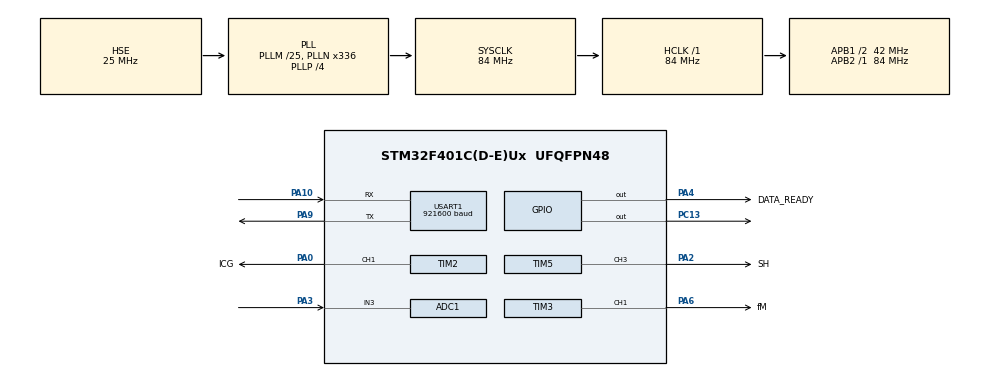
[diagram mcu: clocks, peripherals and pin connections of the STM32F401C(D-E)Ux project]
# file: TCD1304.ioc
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ADC1.Channel-0\#ChannelRegularConversion=ADC_CHANNEL_3
ADC1.ContinuousConvMode=DISABLE
ADC1.DMAContinuousRequests=ENABLE
ADC1.ExternalTrigConv=ADC_EXTERNALTRIGCONV_T4_CC4
ADC1.NbrOfConversionFlag=1
ADC1.Rank-0\#ChannelRegularConversion=1
ADC1.SamplingTime-0\#ChannelRegularConversion=ADC_SAMPLETIME_3CYCLES
ADC1.ScanConvMode=DISABLE
ADC1.master=1
Dma.ADC1.0.Direction=DMA_PERIPH_TO_MEMORY
Dma.ADC1.0.FIFOMode=DMA_FIFOMODE_DISABLE
Dma.ADC1.0.Instance=DMA2_Stream0
Dma.ADC1.0.MemDataAlignment=DMA_MDATAALIGN_HALFWORD
Dma.ADC1.0.MemInc=DMA_MINC_ENABLE
Dma.ADC1.0.Mode=DMA_CIRCULAR
Dma.ADC1.0.PeriphDataAlignment=DMA_PDATAALIGN_HALFWORD
Dma.ADC1.0.PeriphInc=DMA_PINC_DISABLE
Dma.ADC1.0.Priority=DMA_PRIORITY_LOW
Dma.Request0=ADC1
Dma.Request1=USART1_RX
Dma.Request2=USART1_TX
Dma.USART1_RX.1.Direction=DMA_PERIPH_TO_MEMORY
Dma.USART1_RX.1.FIFOMode=DMA_FIFOMODE_DISABLE
Dma.USART1_RX.1.Instance=DMA2_Stream2
Dma.USART1_RX.1.MemDataAlignment=DMA_MDATAALIGN_BYTE
Dma.USART1_RX.1.MemInc=DMA_MINC_ENABLE
Dma.USART1_RX.1.Mode=DMA_NORMAL
Dma.USART1_RX.1.PeriphDataAlignment=DMA_PDATAALIGN_BYTE
Dma.USART1_RX.1.PeriphInc=DMA_PINC_DISABLE
Dma.USART1_RX.1.Priority=DMA_PRIORITY_LOW
Dma.USART1_TX.2.Direction=DMA_MEMORY_TO_PERIPH
Dma.USART1_TX.2.FIFOMode=DMA_FIFOMODE_DISABLE
Dma.USART1_TX.2.Instance=DMA2_Stream7
Dma.USART1_TX.2.MemDataAlignment=DMA_MDATAALIGN_BYTE
Dma.USART1_TX.2.MemInc=DMA_MINC_ENABLE
Dma.USART1_TX.2.Mode=DMA_NORMAL
Dma.USART1_TX.2.PeriphDataAlignment=DMA_PDATAALIGN_BYTE
Dma.USART1_TX.2.PeriphInc=DMA_PINC_DISABLE
Dma.USART1_TX.2.Priority=DMA_PRIORITY_LOW
Mcu.Family=STM32F4
Mcu.Name=STM32F401C(D-E)Ux
Mcu.Package=UFQFPN48
NVIC.DMA2_Stream0_IRQn=true\:0\:0\:false\:false\:true\:false\:true\:true
NVIC.DMA2_Stream2_IRQn=true\:0\:0\:false\:false\:true\:false\:true\:true
NVIC.DMA2_Stream7_IRQn=true\:0\:0\:false\:false\:true\:false\:true\:true
NVIC.PriorityGroup=NVIC_PRIORITYGROUP_4
NVIC.TIM2_IRQn=true\:0\:0\:false\:false\:true\:true\:true\:true
NVIC.USART1_IRQn=true\:0\:0\:false\:false\:true\:true\:true\:true
PA0-WKUP.GPIO_Label=ICG
PA0-WKUP.Signal=S_TIM2_CH1_ETR
PA10.Mode=Asynchronous
PA10.Signal=USART1_RX
PA2.GPIO_Label=SH
PA2.Signal=S_TIM5_CH3
PA3.Signal=ADCx_IN3
PA4.GPIO_Label=DATA_READY
PA4.Signal=GPIO_Output
PA6.GPIO_Label=fM
PA6.Signal=S_TIM3_CH1
PA9.Mode=Asynchronous
PA9.Signal=USART1_TX
PC13-ANTI_TAMP.GPIO_PuPd=GPIO_PULLUP
PC13-ANTI_TAMP.PinState=GPIO_PIN_SET
PC13-ANTI_TAMP.Signal=GPIO_Output
PH0\ -\ OSC_IN.Mode=HSE-External-Oscillator
PH0\ -\ OSC_IN.Signal=RCC_OSC_IN
PH1\ -\ OSC_OUT.Mode=HSE-External-Oscillator
PH1\ -\ OSC_OUT.Signal=RCC_OSC_OUT
ProjectManager.HeapSize=0x200
ProjectManager.StackSize=0x400
ProjectManager.TargetToolchain=STM32CubeIDE
RCC.48MHZClocksFreq_Value=48000000
RCC.AHBFreq_Value=84000000
RCC.APB1CLKDivider=RCC_HCLK_DIV2
RCC.APB1Freq_Value=42000000
RCC.APB1TimFreq_Value=84000000
RCC.APB2Freq_Value=84000000
RCC.APB2TimFreq_Value=84000000
RCC.CortexFreq_Value=84000000
RCC.HCLKFreq_Value=84000000
RCC.HSE_VALUE=25000000
RCC.HSI_VALUE=16000000
RCC.LSE_VALUE=32768
RCC.PLLM=25
RCC.PLLN=336
RCC.PLLP=RCC_PLLP_DIV4
RCC.PLLQ=7
RCC.PLLSourceVirtual=RCC_PLLSOURCE_HSE
RCC.SYSCLKFreq_VALUE=84000000
RCC.SYSCLKSource=RCC_SYSCLKSOURCE_PLLCLK
RCC.VCOOutputFreq_Value=336000000
SH.ADCx_IN3.0=ADC1_IN3,IN3
SH.S_TIM2_CH1_ETR.0=TIM2_CH1,PWM Generation1 CH1
SH.S_TIM3_CH1.0=TIM3_CH1,PWM Generation1 CH1
SH.S_TIM5_CH3.0=TIM5_CH3,PWM Generation3 CH3
TIM2.Channel-PWM\ Generation1\ CH1=TIM_CHANNEL_1
TIM2.Period=ccd_config.icg_period-1
TIM2.Pulse-PWM\ Generation1\ CH1=840-1
TIM2.TIM_MasterOutputTrigger=TIM_TRGO_ENABLE
TIM2.TIM_MasterSlaveMode=TIM_MASTERSLAVEMODE_ENABLE
TIM3.Channel-PWM\ Generation1\ CH1=TIM_CHANNEL_1
TIM3.Period=42-1
TIM3.Pulse-PWM\ Generation1\ CH1=21-1
TIM4.Channel-PWM\ Generation4\ No\ Output=TIM_CHANNEL_4
TIM4.Period=168-1
TIM4.Pulse-PWM\ Generation4\ No\ Output=42-1
TIM5.Channel-PWM\ Generation3\ CH3=TIM_CHANNEL_3
TIM5.OCPolarity_3=TIM_OCPOLARITY_LOW
TIM5.Period=ccd_config.sh_period-1
TIM5.Pulse-PWM\ Generation3\ CH3=336-1
TIM5.TIM_MasterSlaveMode=TIM_MASTERSLAVEMODE_ENABLE
USART1.BaudRate=921600
USART1.VirtualMode=VM_ASYNC
VP_TIM2_VS_ClockSourceINT.Mode=Internal
VP_TIM3_VS_ClockSourceINT.Mode=Internal
VP_TIM4_VS_ClockSourceINT.Mode=Internal
VP_TIM4_VS_no_output4.Mode=PWM Generation4 No Output
VP_TIM5_VS_ClockSourceINT.Mode=Internal
VP_TIM5_VS_ClockSourceITR.Mode=TriggerSource_ITR0
VP_TIM5_VS_ControllerModeTrigger.Mode=Trigger Mode
board=custom

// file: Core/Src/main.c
/* USER CODE BEGIN Header */
/**
 ******************************************************************************
 * @file           : main.c
 * @brief          : Main program body
 ******************************************************************************
 * @attention
 *
 * Copyright (c) 2023 STMicroelectronics.
 * All rights reserved.
 *
 * This software is licensed under terms that can be found in the LICENSE file
 * in the root directory of this software component.
 * If no LICENSE file comes with this software, it is provided AS-IS.
 *
 ******************************************************************************
 */
/* USER CODE END Header */
#include "main.h"

/* USER CODE BEGIN Includes */

#include "TCD1304.h"

/* USER CODE END Includes */

ADC_HandleTypeDef hadc1;
DMA_HandleTypeDef hdma_adc1;

TIM_HandleTypeDef htim2;
TIM_HandleTypeDef htim3;
TIM_HandleTypeDef htim4;
TIM_HandleTypeDef htim5;

UART_HandleTypeDef huart1;
DMA_HandleTypeDef hdma_usart1_rx;
DMA_HandleTypeDef hdma_usart1_tx;

void SystemClock_Config(void);
static void MX_GPIO_Init(void);
static void MX_DMA_Init(void);
static void MX_TIM2_Init(void);
static void MX_TIM3_Init(void);
static void MX_TIM4_Init(void);
static void MX_TIM5_Init(void);
static void MX_ADC1_Init(void);
static void MX_USART1_UART_Init(void);

int main(void)
{

  /* MCU Configuration--------------------------------------------------------*/

  /* Reset of all peripherals, Initializes the Flash interface and the Systick. */
  HAL_Init();

  /* Configure the system clock */
  SystemClock_Config();

  /* Initialize all configured peripherals */
  MX_GPIO_Init();
  MX_DMA_Init();
  MX_TIM2_Init();
  MX_TIM3_Init();
  MX_TIM4_Init();
  MX_TIM5_Init();
  MX_ADC1_Init();
  MX_USART1_UART_Init();
  /* USER CODE BEGIN 2 */

	tcd1304_setup();

  /* USER CODE END 2 */

  /* Infinite loop */
	while (1) {

    /* USER CODE BEGIN 3 */
		tcd1304_loop();
	}
  /* USER CODE END 3 */
}

void SystemClock_Config(void)
{
  RCC_OscInitTypeDef RCC_OscInitStruct = {0};
  RCC_ClkInitTypeDef RCC_ClkInitStruct = {0};

  /** Configure the main internal regulator output voltage
  */
  __HAL_RCC_PWR_CLK_ENABLE();
  __HAL_PWR_VOLTAGESCALING_CONFIG(PWR_REGULATOR_VOLTAGE_SCALE2);

  /** Initializes the RCC Oscillators according to the specified parameters
  * in the RCC_OscInitTypeDef structure.
  */
  RCC_OscInitStruct.OscillatorType = RCC_OSCILLATORTYPE_HSE;
  RCC_OscInitStruct.HSEState = RCC_HSE_ON;
  RCC_OscInitStruct.PLL.PLLState = RCC_PLL_ON;
  RCC_OscInitStruct.PLL.PLLSource = RCC_PLLSOURCE_HSE;
  RCC_OscInitStruct.PLL.PLLM = 25;
  RCC_OscInitStruct.PLL.PLLN = 336;
  RCC_OscInitStruct.PLL.PLLP = RCC_PLLP_DIV4;
  RCC_OscInitStruct.PLL.PLLQ = 7;
  if (HAL_RCC_OscConfig(&RCC_OscInitStruct) != HAL_OK)
  {
    Error_Handler();
  }

  /** Initializes the CPU, AHB and APB buses clocks
  */
  RCC_ClkInitStruct.ClockType = RCC_CLOCKTYPE_HCLK|RCC_CLOCKTYPE_SYSCLK
                              |RCC_CLOCKTYPE_PCLK1|RCC_CLOCKTYPE_PCLK2;
  RCC_ClkInitStruct.SYSCLKSource = RCC_SYSCLKSOURCE_PLLCLK;
  RCC_ClkInitStruct.AHBCLKDivider = RCC_SYSCLK_DIV1;
  RCC_ClkInitStruct.APB1CLKDivider = RCC_HCLK_DIV2;
  RCC_ClkInitStruct.APB2CLKDivider = RCC_HCLK_DIV1;

  if (HAL_RCC_ClockConfig(&RCC_ClkInitStruct, FLASH_LATENCY_2) != HAL_OK)
  {
    Error_Handler();
  }
}

static void MX_ADC1_Init(void)
{

  ADC_ChannelConfTypeDef sConfig = {0};

  /** Configure the global features of the ADC (Clock, Resolution, Data Alignment and number of conversion)
  */
  hadc1.Instance = ADC1;
  hadc1.Init.ClockPrescaler = ADC_CLOCK_SYNC_PCLK_DIV4;
  hadc1.Init.Resolution = ADC_RESOLUTION_12B;
  hadc1.Init.ScanConvMode = DISABLE;
  hadc1.Init.ContinuousConvMode = DISABLE;
  hadc1.Init.DiscontinuousConvMode = DISABLE;
  hadc1.Init.ExternalTrigConvEdge = ADC_EXTERNALTRIGCONVEDGE_RISING;
  hadc1.Init.ExternalTrigConv = ADC_EXTERNALTRIGCONV_T4_CC4;
  hadc1.Init.DataAlign = ADC_DATAALIGN_RIGHT;
  hadc1.Init.NbrOfConversion = 1;
  hadc1.Init.DMAContinuousRequests = ENABLE;
  hadc1.Init.EOCSelection = ADC_EOC_SINGLE_CONV;
  if (HAL_ADC_Init(&hadc1) != HAL_OK)
  {
    Error_Handler();
  }

  /** Configure for the selected ADC regular channel its corresponding rank in the sequencer and its sample time.
  */
  sConfig.Channel = ADC_CHANNEL_3;
  sConfig.Rank = 1;
  sConfig.SamplingTime = ADC_SAMPLETIME_3CYCLES;
  if (HAL_ADC_ConfigChannel(&hadc1, &sConfig) != HAL_OK)
  {
    Error_Handler();
  }

}

static void MX_TIM2_Init(void)
{

  TIM_ClockConfigTypeDef sClockSourceConfig = {0};
  TIM_MasterConfigTypeDef sMasterConfig = {0};
  TIM_OC_InitTypeDef sConfigOC = {0};

  htim2.Instance = TIM2;
  htim2.Init.Prescaler = 0;
  htim2.Init.CounterMode = TIM_COUNTERMODE_UP;
  htim2.Init.Period = ccd_config.icg_period-1;
  htim2.Init.ClockDivision = TIM_CLOCKDIVISION_DIV1;
  htim2.Init.AutoReloadPreload = TIM_AUTORELOAD_PRELOAD_DISABLE;
  if (HAL_TIM_Base_Init(&htim2) != HAL_OK)
  {
    Error_Handler();
  }
  sClockSourceConfig.ClockSource = TIM_CLOCKSOURCE_INTERNAL;
  if (HAL_TIM_ConfigClockSource(&htim2, &sClockSourceConfig) != HAL_OK)
  {
    Error_Handler();
  }
  if (HAL_TIM_PWM_Init(&htim2) != HAL_OK)
  {
    Error_Handler();
  }
  sMasterConfig.MasterOutputTrigger = TIM_TRGO_ENABLE;
  sMasterConfig.MasterSlaveMode = TIM_MASTERSLAVEMODE_ENABLE;
  if (HAL_TIMEx_MasterConfigSynchronization(&htim2, &sMasterConfig) != HAL_OK)
  {
    Error_Handler();
  }
  sConfigOC.OCMode = TIM_OCMODE_PWM1;
  sConfigOC.Pulse = 840-1;
  sConfigOC.OCPolarity = TIM_OCPOLARITY_HIGH;
  sConfigOC.OCFastMode = TIM_OCFAST_DISABLE;
  if (HAL_TIM_PWM_ConfigChannel(&htim2, &sConfigOC, TIM_CHANNEL_1) != HAL_OK)
  {
    Error_Handler();
  }
  HAL_TIM_MspPostInit(&htim2);

}

static void MX_TIM3_Init(void)
{

  TIM_ClockConfigTypeDef sClockSourceConfig = {0};
  TIM_MasterConfigTypeDef sMasterConfig = {0};
  TIM_OC_InitTypeDef sConfigOC = {0};

  htim3.Instance = TIM3;
  htim3.Init.Prescaler = 0;
  htim3.Init.CounterMode = TIM_COUNTERMODE_UP;
  htim3.Init.Period = 42-1;
  htim3.Init.ClockDivision = TIM_CLOCKDIVISION_DIV1;
  htim3.Init.AutoReloadPreload = TIM_AUTORELOAD_PRELOAD_DISABLE;
  if (HAL_TIM_Base_Init(&htim3) != HAL_OK)
  {
    Error_Handler();
  }
  sClockSourceConfig.ClockSource = TIM_CLOCKSOURCE_INTERNAL;
  if (HAL_TIM_ConfigClockSource(&htim3, &sClockSourceConfig) != HAL_OK)
  {
    Error_Handler();
  }
  if (HAL_TIM_PWM_Init(&htim3) != HAL_OK)
  {
    Error_Handler();
  }
  sMasterConfig.MasterOutputTrigger = TIM_TRGO_RESET;
  sMasterConfig.MasterSlaveMode = TIM_MASTERSLAVEMODE_DISABLE;
  if (HAL_TIMEx_MasterConfigSynchronization(&htim3, &sMasterConfig) != HAL_OK)
  {
    Error_Handler();
  }
  sConfigOC.OCMode = TIM_OCMODE_PWM1;
  sConfigOC.Pulse = 21-1;
  sConfigOC.OCPolarity = TIM_OCPOLARITY_HIGH;
  sConfigOC.OCFastMode = TIM_OCFAST_DISABLE;
  if (HAL_TIM_PWM_ConfigChannel(&htim3, &sConfigOC, TIM_CHANNEL_1) != HAL_OK)
  {
    Error_Handler();
  }
  HAL_TIM_MspPostInit(&htim3);

}

static void MX_TIM4_Init(void)
{

  TIM_ClockConfigTypeDef sClockSourceConfig = {0};
  TIM_MasterConfigTypeDef sMasterConfig = {0};
  TIM_OC_InitTypeDef sConfigOC = {0};

  htim4.Instance = TIM4;
  htim4.Init.Prescaler = 0;
  htim4.Init.CounterMode = TIM_COUNTERMODE_UP;
  htim4.Init.Period = 168-1;
  htim4.Init.ClockDivision = TIM_CLOCKDIVISION_DIV1;
  htim4.Init.AutoReloadPreload = TIM_AUTORELOAD_PRELOAD_DISABLE;
  if (HAL_TIM_Base_Init(&htim4) != HAL_OK)
  {
    Error_Handler();
  }
  sClockSourceConfig.ClockSource = TIM_CLOCKSOURCE_INTERNAL;
  if (HAL_TIM_ConfigClockSource(&htim4, &sClockSourceConfig) != HAL_OK)
  {
    Error_Handler();
  }
  if (HAL_TIM_PWM_Init(&htim4) != HAL_OK)
  {
    Error_Handler();
  }
  sMasterConfig.MasterOutputTrigger = TIM_TRGO_RESET;
  sMasterConfig.MasterSlaveMode = TIM_MASTERSLAVEMODE_DISABLE;
  if (HAL_TIMEx_MasterConfigSynchronization(&htim4, &sMasterConfig) != HAL_OK)
  {
    Error_Handler();
  }
  sConfigOC.OCMode = TIM_OCMODE_PWM1;
  sConfigOC.Pulse = 42-1;
  sConfigOC.OCPolarity = TIM_OCPOLARITY_HIGH;
  sConfigOC.OCFastMode = TIM_OCFAST_DISABLE;
  if (HAL_TIM_PWM_ConfigChannel(&htim4, &sConfigOC, TIM_CHANNEL_4) != HAL_OK)
  {
    Error_Handler();
  }

}

static void MX_TIM5_Init(void)
{

  TIM_ClockConfigTypeDef sClockSourceConfig = {0};
  TIM_SlaveConfigTypeDef sSlaveConfig = {0};
  TIM_MasterConfigTypeDef sMasterConfig = {0};
  TIM_OC_InitTypeDef sConfigOC = {0};

  htim5.Instance = TIM5;
  htim5.Init.Prescaler = 0;
  htim5.Init.CounterMode = TIM_COUNTERMODE_UP;
  htim5.Init.Period = ccd_config.sh_period-1;
  htim5.Init.ClockDivision = TIM_CLOCKDIVISION_DIV1;
  htim5.Init.AutoReloadPreload = TIM_AUTORELOAD_PRELOAD_DISABLE;
  if (HAL_TIM_Base_Init(&htim5) != HAL_OK)
  {
    Error_Handler();
  }
  sClockSourceConfig.ClockSource = TIM_CLOCKSOURCE_INTERNAL;
  if (HAL_TIM_ConfigClockSource(&htim5, &sClockSourceConfig) != HAL_OK)
  {
    Error_Handler();
  }
  if (HAL_TIM_PWM_Init(&htim5) != HAL_OK)
  {
    Error_Handler();
  }
  sSlaveConfig.SlaveMode = TIM_SLAVEMODE_TRIGGER;
  sSlaveConfig.InputTrigger = TIM_TS_ITR0;
  if (HAL_TIM_SlaveConfigSynchro(&htim5, &sSlaveConfig) != HAL_OK)
  {
    Error_Handler();
  }
  sMasterConfig.MasterOutputTrigger = TIM_TRGO_RESET;
  sMasterConfig.MasterSlaveMode = TIM_MASTERSLAVEMODE_ENABLE;
  if (HAL_TIMEx_MasterConfigSynchronization(&htim5, &sMasterConfig) != HAL_OK)
  {
    Error_Handler();
  }
  sConfigOC.OCMode = TIM_OCMODE_PWM1;
  sConfigOC.Pulse = 336-1;
  sConfigOC.OCPolarity = TIM_OCPOLARITY_LOW;
  sConfigOC.OCFastMode = TIM_OCFAST_DISABLE;
  if (HAL_TIM_PWM_ConfigChannel(&htim5, &sConfigOC, TIM_CHANNEL_3) != HAL_OK)
  {
    Error_Handler();
  }
  HAL_TIM_MspPostInit(&htim5);

}

static void MX_USART1_UART_Init(void)
{

  huart1.Instance = USART1;
  huart1.Init.BaudRate = 921600;
  huart1.Init.WordLength = UART_WORDLENGTH_8B;
  huart1.Init.StopBits = UART_STOPBITS_1;
  huart1.Init.Parity = UART_PARITY_NONE;
  huart1.Init.Mode = UART_MODE_TX_RX;
  huart1.Init.HwFlowCtl = UART_HWCONTROL_NONE;
  huart1.Init.OverSampling = UART_OVERSAMPLING_16;
  if (HAL_UART_Init(&huart1) != HAL_OK)
  {
    Error_Handler();
  }

}

static void MX_DMA_Init(void)
{

  /* DMA controller clock enable */
  __HAL_RCC_DMA2_CLK_ENABLE();

  /* DMA interrupt init */
  /* DMA2_Stream0_IRQn interrupt configuration */
  HAL_NVIC_SetPriority(DMA2_Stream0_IRQn, 0, 0);
  HAL_NVIC_EnableIRQ(DMA2_Stream0_IRQn);
  /* DMA2_Stream2_IRQn interrupt configuration */
  HAL_NVIC_SetPriority(DMA2_Stream2_IRQn, 0, 0);
  HAL_NVIC_EnableIRQ(DMA2_Stream2_IRQn);
  /* DMA2_Stream7_IRQn interrupt configuration */
  HAL_NVIC_SetPriority(DMA2_Stream7_IRQn, 0, 0);
  HAL_NVIC_EnableIRQ(DMA2_Stream7_IRQn);

}

static void MX_GPIO_Init(void)
{
  GPIO_InitTypeDef GPIO_InitStruct = {0};

  /* GPIO Ports Clock Enable */
  __HAL_RCC_GPIOC_CLK_ENABLE();
  __HAL_RCC_GPIOH_CLK_ENABLE();
  __HAL_RCC_GPIOA_CLK_ENABLE();

  /*Configure GPIO pin Output Level */
  HAL_GPIO_WritePin(GPIOC, GPIO_PIN_13, GPIO_PIN_SET);

  /*Configure GPIO pin Output Level */
  HAL_GPIO_WritePin(DATA_READY_GPIO_Port, DATA_READY_Pin, GPIO_PIN_RESET);

  /*Configure GPIO pin : PC13 */
  GPIO_InitStruct.Pin = GPIO_PIN_13;
  GPIO_InitStruct.Mode = GPIO_MODE_OUTPUT_PP;
  GPIO_InitStruct.Pull = GPIO_PULLUP;
  GPIO_InitStruct.Speed = GPIO_SPEED_FREQ_LOW;
  HAL_GPIO_Init(GPIOC, &GPIO_InitStruct);

  /*Configure GPIO pin : DATA_READY_Pin */
  GPIO_InitStruct.Pin = DATA_READY_Pin;
  GPIO_InitStruct.Mode = GPIO_MODE_OUTPUT_PP;
  GPIO_InitStruct.Pull = GPIO_NOPULL;
  GPIO_InitStruct.Speed = GPIO_SPEED_FREQ_LOW;
  HAL_GPIO_Init(DATA_READY_GPIO_Port, &GPIO_InitStruct);

}

/* USER CODE BEGIN 4 */

void init_icg_sh() {
	MX_TIM2_Init();
	MX_TIM5_Init();
}

void init_adc_tim() {
	MX_TIM4_Init();
}

/* USER CODE END 4 */

void Error_Handler(void)
{
	__disable_irq();
	while (1) {
	}
}
